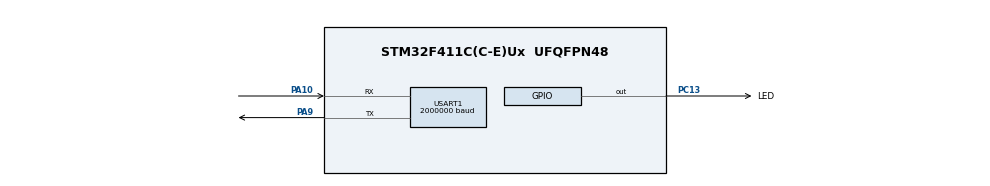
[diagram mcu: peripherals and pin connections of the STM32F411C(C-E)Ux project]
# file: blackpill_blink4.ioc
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Mcu.Family=STM32F4
Mcu.Name=STM32F411C(C-E)Ux
Mcu.Package=UFQFPN48
NVIC.PriorityGroup=NVIC_PRIORITYGROUP_4
PA10.Mode=Asynchronous
PA10.Signal=USART1_RX
PA13.Mode=Serial_Wire
PA13.Signal=SYS_JTMS-SWDIO
PA14.Mode=Serial_Wire
PA14.Signal=SYS_JTCK-SWCLK
PA9.Mode=Asynchronous
PA9.Signal=USART1_TX
PC13-ANTI_TAMP.GPIO_Label=LED
PC13-ANTI_TAMP.GPIO_ModeDefaultOutputPP=GPIO_MODE_OUTPUT_OD
PC13-ANTI_TAMP.GPIO_PuPd=GPIO_NOPULL
PC13-ANTI_TAMP.PinState=GPIO_PIN_SET
PC13-ANTI_TAMP.Signal=GPIO_Output
PH0\ -\ OSC_IN.Mode=HSE-External-Oscillator
PH0\ -\ OSC_IN.Signal=RCC_OSC_IN
PH1\ -\ OSC_OUT.Mode=HSE-External-Oscillator
PH1\ -\ OSC_OUT.Signal=RCC_OSC_OUT
ProjectManager.HeapSize=0x200
ProjectManager.StackSize=0x400
ProjectManager.TargetToolchain=STM32CubeIDE
RCC.48MHZClocksFreq_Value=50000000
RCC.AHBFreq_Value=100000000
RCC.APB1CLKDivider=RCC_HCLK_DIV2
RCC.APB1Freq_Value=50000000
RCC.APB1TimFreq_Value=100000000
RCC.APB2Freq_Value=100000000
RCC.APB2TimFreq_Value=100000000
RCC.CortexFreq_Value=100000000
RCC.HCLKFreq_Value=100000000
RCC.HSE_VALUE=25000000
RCC.HSI_VALUE=16000000
RCC.LSE_VALUE=32768
RCC.PLLM=12
RCC.PLLN=96
RCC.PLLSourceVirtual=RCC_PLLSOURCE_HSE
RCC.SYSCLKFreq_VALUE=100000000
RCC.SYSCLKSource=RCC_SYSCLKSOURCE_PLLCLK
RCC.VCOOutputFreq_Value=200000000
USART1.BaudRate=2000000
USART1.VirtualMode=VM_ASYNC
board=custom

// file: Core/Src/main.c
/* USER CODE BEGIN Header */
/**
 ******************************************************************************
 * @file           : main.c
 * @brief          : Main program body
 ******************************************************************************
 * @attention
 *
 * Copyright (c) 2024 Lars Boegild Thomsen <lth@stm32world.com>
 * All rights reserved.
 *
 * This software is licensed under terms that can be found in the LICENSE file
 * in the root directory of this software component.
 * If no LICENSE file comes with this software, it is provided AS-IS.
 *
 ******************************************************************************
 */
/* USER CODE END Header */
#include "main.h"

/* USER CODE BEGIN Includes */
#include <stdio.h>
#include "stm32f4xx_it.h"
/* USER CODE END Includes */

void SystemClock_Config(void);
static void MX_GPIO_Init(void);
static void MX_USART1_UART_Init(void);

/* USER CODE BEGIN 0 */

int __io_putchar(int ch) {

    LL_USART_TransmitData8(USART1, ch);

    uint32_t start = uwTick;
    uint8_t timeout = 0;

    uint32_t active_flag = LL_USART_IsActiveFlag_TC(USART1);
    // Wait until character has been transmitted
    while (active_flag == 0 && !timeout) {
        active_flag = LL_USART_IsActiveFlag_TC(USART1);
        timeout = uwTick - start <= 100 ? 0 : 1;
    }

    if (timeout) return 0;

    return ch;

}

/* USER CODE END 0 */

int main(void)
{

    /* MCU Configuration--------------------------------------------------------*/

    /* Reset of all peripherals, Initializes the Flash interface and the Systick. */
    LL_APB2_GRP1_EnableClock(LL_APB2_GRP1_PERIPH_SYSCFG);
    LL_APB1_GRP1_EnableClock(LL_APB1_GRP1_PERIPH_PWR);

    /* System interrupt init*/
    NVIC_SetPriorityGrouping(NVIC_PRIORITYGROUP_4);

    /* SysTick_IRQn interrupt configuration */
    NVIC_SetPriority(SysTick_IRQn, NVIC_EncodePriority(NVIC_GetPriorityGrouping(), 15, 0));

    /* Configure the system clock */
    SystemClock_Config();

    /* Initialize all configured peripherals */
    MX_GPIO_Init();
    MX_USART1_UART_Init();
    /* USER CODE BEGIN 2 */

    LL_SYSTICK_EnableIT();

    printf("Starting blink4\n");

    /* USER CODE END 2 */

    /* Infinite loop */
    /* USER CODE BEGIN WHILE */

    uint32_t now = 0, next_blink = 500, next_tick = 1000, loop_cnt = 0;

    while (1) {

        now = uwTick;

        if (now >= next_blink) {

            //printf("Toggling GPIO\n");

            LL_GPIO_TogglePin(LED_GPIO_Port, LED_Pin);

            next_blink = now + 500;
        }

        if (now >= next_tick) {

            printf("Tick %lu (loop count = %lu)\n", now / 1000, loop_cnt);

            loop_cnt = 0;
            next_tick = now + 1000;

        }

        ++loop_cnt;

        /* USER CODE END WHILE */

    }
}

void SystemClock_Config(void)
{
    LL_FLASH_SetLatency(LL_FLASH_LATENCY_3);
    while (LL_FLASH_GetLatency() != LL_FLASH_LATENCY_3)
    {
    }
    LL_PWR_SetRegulVoltageScaling(LL_PWR_REGU_VOLTAGE_SCALE1);
    LL_RCC_HSE_Enable();

    /* Wait till HSE is ready */
    while (LL_RCC_HSE_IsReady() != 1)
    {

    }
    LL_RCC_PLL_ConfigDomain_SYS(LL_RCC_PLLSOURCE_HSE, LL_RCC_PLLM_DIV_12, 96, LL_RCC_PLLP_DIV_2);
    LL_RCC_PLL_Enable();

    /* Wait till PLL is ready */
    while (LL_RCC_PLL_IsReady() != 1)
    {

    }
    while (LL_PWR_IsActiveFlag_VOS() == 0)
    {
    }
    LL_RCC_SetAHBPrescaler(LL_RCC_SYSCLK_DIV_1);
    LL_RCC_SetAPB1Prescaler(LL_RCC_APB1_DIV_2);
    LL_RCC_SetAPB2Prescaler(LL_RCC_APB2_DIV_1);
    LL_RCC_SetSysClkSource(LL_RCC_SYS_CLKSOURCE_PLL);

    /* Wait till System clock is ready */
    while (LL_RCC_GetSysClkSource() != LL_RCC_SYS_CLKSOURCE_STATUS_PLL)
    {

    }
    LL_Init1msTick(100000000);
    LL_SetSystemCoreClock(100000000);
    LL_RCC_SetTIMPrescaler(LL_RCC_TIM_PRESCALER_TWICE);
}

static void MX_USART1_UART_Init(void)
{

    LL_USART_InitTypeDef USART_InitStruct = { 0 };

    LL_GPIO_InitTypeDef GPIO_InitStruct = { 0 };

    /* Peripheral clock enable */
    LL_APB2_GRP1_EnableClock(LL_APB2_GRP1_PERIPH_USART1);

    LL_AHB1_GRP1_EnableClock(LL_AHB1_GRP1_PERIPH_GPIOA);
    /**USART1 GPIO Configuration
     PA9   ------> USART1_TX
     PA10   ------> USART1_RX
     */
    GPIO_InitStruct.Pin = LL_GPIO_PIN_9 | LL_GPIO_PIN_10;
    GPIO_InitStruct.Mode = LL_GPIO_MODE_ALTERNATE;
    GPIO_InitStruct.Speed = LL_GPIO_SPEED_FREQ_VERY_HIGH;
    GPIO_InitStruct.OutputType = LL_GPIO_OUTPUT_PUSHPULL;
    GPIO_InitStruct.Pull = LL_GPIO_PULL_NO;
    GPIO_InitStruct.Alternate = LL_GPIO_AF_7;
    LL_GPIO_Init(GPIOA, &GPIO_InitStruct);

    USART_InitStruct.BaudRate = 2000000;
    USART_InitStruct.DataWidth = LL_USART_DATAWIDTH_8B;
    USART_InitStruct.StopBits = LL_USART_STOPBITS_1;
    USART_InitStruct.Parity = LL_USART_PARITY_NONE;
    USART_InitStruct.TransferDirection = LL_USART_DIRECTION_TX_RX;
    USART_InitStruct.HardwareFlowControl = LL_USART_HWCONTROL_NONE;
    USART_InitStruct.OverSampling = LL_USART_OVERSAMPLING_16;
    LL_USART_Init(USART1, &USART_InitStruct);
    LL_USART_ConfigAsyncMode(USART1);
    LL_USART_Enable(USART1);

}

static void MX_GPIO_Init(void)
{
    LL_GPIO_InitTypeDef GPIO_InitStruct = { 0 };

    /* GPIO Ports Clock Enable */
    LL_AHB1_GRP1_EnableClock(LL_AHB1_GRP1_PERIPH_GPIOC);
    LL_AHB1_GRP1_EnableClock(LL_AHB1_GRP1_PERIPH_GPIOH);
    LL_AHB1_GRP1_EnableClock(LL_AHB1_GRP1_PERIPH_GPIOA);

    /**/
    LL_GPIO_SetOutputPin(LED_GPIO_Port, LED_Pin);

    /**/
    GPIO_InitStruct.Pin = LED_Pin;
    GPIO_InitStruct.Mode = LL_GPIO_MODE_OUTPUT;
    GPIO_InitStruct.Speed = LL_GPIO_SPEED_FREQ_LOW;
    GPIO_InitStruct.OutputType = LL_GPIO_OUTPUT_OPENDRAIN;
    GPIO_InitStruct.Pull = LL_GPIO_PULL_NO;
    LL_GPIO_Init(LED_GPIO_Port, &GPIO_InitStruct);

}

void Error_Handler(void)
{
    __disable_irq();
    while (1) {
    }
}
